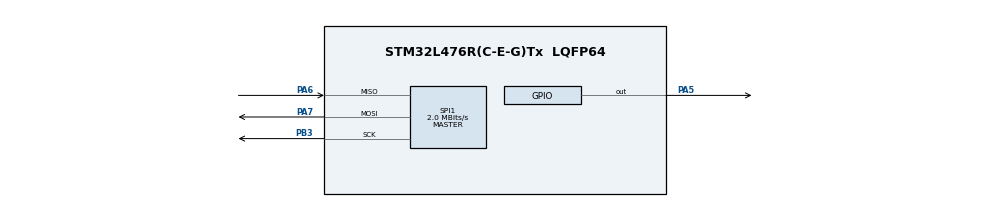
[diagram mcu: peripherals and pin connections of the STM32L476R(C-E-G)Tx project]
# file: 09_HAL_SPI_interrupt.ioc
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Mcu.Family=STM32L4
Mcu.Name=STM32L476R(C-E-G)Tx
Mcu.Package=LQFP64
NVIC.PriorityGroup=NVIC_PRIORITYGROUP_4
NVIC.SPI1_IRQn=true\:0\:0\:false\:true\:true\:1\:true\:true\:true
PA5.Signal=GPIO_Output
PA6.Mode=Full_Duplex_Master
PA6.Signal=SPI1_MISO
PA7.Mode=Full_Duplex_Master
PA7.Signal=SPI1_MOSI
PB3\ (JTDO-TRACESWO).Mode=Full_Duplex_Master
PB3\ (JTDO-TRACESWO).Signal=SPI1_SCK
ProjectManager.HeapSize=0x200
ProjectManager.StackSize=0x400
ProjectManager.TargetToolchain=STM32CubeIDE
RCC.HSE_VALUE=8000000
RCC.HSI_VALUE=16000000
RCC.LSE_VALUE=32768
RCC.MSI_VALUE=4000000
RCC.VCOOutputFreq_Value=32000000
SPI1.CalculateBaudRate=2.0 MBits/s
SPI1.DataSize=SPI_DATASIZE_8BIT
SPI1.Direction=SPI_DIRECTION_2LINES
SPI1.Mode=SPI_MODE_MASTER
SPI1.VirtualType=VM_MASTER
board=custom

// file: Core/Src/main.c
/* USER CODE BEGIN Header */
/**
  ******************************************************************************
  * @file           : main.c
  * @brief          : Main program body
  ******************************************************************************
  * @attention
  *
  * Copyright (c) 2026 STMicroelectronics.
  * All rights reserved.
  *
  * This software is licensed under terms that can be found in the LICENSE file
  * in the root directory of this software component.
  * If no LICENSE file comes with this software, it is provided AS-IS.
  *
  ******************************************************************************
  */
/* USER CODE END Header */
#include "main.h"

SPI_HandleTypeDef hspi1;

void SystemClock_Config(void);
static void MX_GPIO_Init(void);
static void MX_SPI1_Init(void);
static void MX_NVIC_Init(void);

/* USER CODE BEGIN 0 */
uint8_t txData[] = "HELLO";
/* USER CODE END 0 */

int main(void)
{

  /* MCU Configuration--------------------------------------------------------*/

  /* Reset of all peripherals, Initializes the Flash interface and the Systick. */
  HAL_Init();

  /* Configure the system clock */
  SystemClock_Config();

  /* Initialize all configured peripherals */
  MX_GPIO_Init();
  MX_SPI1_Init();

  /* Initialize interrupts */
  MX_NVIC_Init();

  /* Infinite loop */
  /* USER CODE BEGIN WHILE */
  while (1)
  {
	    while (1)
	    {
	        HAL_SPI_Transmit_IT(&hspi1, txData, sizeof(txData));

	        HAL_Delay(1000);
	    }

    /* USER CODE END WHILE */

  }
}

void SystemClock_Config(void)
{
  RCC_OscInitTypeDef RCC_OscInitStruct = {0};
  RCC_ClkInitTypeDef RCC_ClkInitStruct = {0};

  /** Configure the main internal regulator output voltage
  */
  if (HAL_PWREx_ControlVoltageScaling(PWR_REGULATOR_VOLTAGE_SCALE1) != HAL_OK)
  {
    Error_Handler();
  }

  /** Initializes the RCC Oscillators according to the specified parameters
  * in the RCC_OscInitTypeDef structure.
  */
  RCC_OscInitStruct.OscillatorType = RCC_OSCILLATORTYPE_MSI;
  RCC_OscInitStruct.MSIState = RCC_MSI_ON;
  RCC_OscInitStruct.MSICalibrationValue = 0;
  RCC_OscInitStruct.MSIClockRange = RCC_MSIRANGE_6;
  RCC_OscInitStruct.PLL.PLLState = RCC_PLL_NONE;
  if (HAL_RCC_OscConfig(&RCC_OscInitStruct) != HAL_OK)
  {
    Error_Handler();
  }

  /** Initializes the CPU, AHB and APB buses clocks
  */
  RCC_ClkInitStruct.ClockType = RCC_CLOCKTYPE_HCLK|RCC_CLOCKTYPE_SYSCLK
                              |RCC_CLOCKTYPE_PCLK1|RCC_CLOCKTYPE_PCLK2;
  RCC_ClkInitStruct.SYSCLKSource = RCC_SYSCLKSOURCE_MSI;
  RCC_ClkInitStruct.AHBCLKDivider = RCC_SYSCLK_DIV1;
  RCC_ClkInitStruct.APB1CLKDivider = RCC_HCLK_DIV1;
  RCC_ClkInitStruct.APB2CLKDivider = RCC_HCLK_DIV1;

  if (HAL_RCC_ClockConfig(&RCC_ClkInitStruct, FLASH_LATENCY_0) != HAL_OK)
  {
    Error_Handler();
  }
}

/**
  * @brief NVIC Configuration.
  * @retval None
  */
static void MX_NVIC_Init(void)
{
  /* SPI1_IRQn interrupt configuration */
  HAL_NVIC_SetPriority(SPI1_IRQn, 0, 0);
  HAL_NVIC_EnableIRQ(SPI1_IRQn);
}

static void MX_SPI1_Init(void)
{

  /* SPI1 parameter configuration*/
  hspi1.Instance = SPI1;
  hspi1.Init.Mode = SPI_MODE_MASTER;
  hspi1.Init.Direction = SPI_DIRECTION_2LINES;
  hspi1.Init.DataSize = SPI_DATASIZE_8BIT;
  hspi1.Init.CLKPolarity = SPI_POLARITY_LOW;
  hspi1.Init.CLKPhase = SPI_PHASE_1EDGE;
  hspi1.Init.NSS = SPI_NSS_SOFT;
  hspi1.Init.BaudRatePrescaler = SPI_BAUDRATEPRESCALER_2;
  hspi1.Init.FirstBit = SPI_FIRSTBIT_MSB;
  hspi1.Init.TIMode = SPI_TIMODE_DISABLE;
  hspi1.Init.CRCCalculation = SPI_CRCCALCULATION_DISABLE;
  hspi1.Init.CRCPolynomial = 7;
  hspi1.Init.CRCLength = SPI_CRC_LENGTH_DATASIZE;
  hspi1.Init.NSSPMode = SPI_NSS_PULSE_ENABLE;
  if (HAL_SPI_Init(&hspi1) != HAL_OK)
  {
    Error_Handler();
  }

}

static void MX_GPIO_Init(void)
{
  GPIO_InitTypeDef GPIO_InitStruct = {0};

  /* GPIO Ports Clock Enable */
  __HAL_RCC_GPIOA_CLK_ENABLE();
  __HAL_RCC_GPIOB_CLK_ENABLE();

  /*Configure GPIO pin Output Level */
  HAL_GPIO_WritePin(GPIOA, GPIO_PIN_5, GPIO_PIN_RESET);

  /*Configure GPIO pin : PA5 */
  GPIO_InitStruct.Pin = GPIO_PIN_5;
  GPIO_InitStruct.Mode = GPIO_MODE_OUTPUT_PP;
  GPIO_InitStruct.Pull = GPIO_NOPULL;
  GPIO_InitStruct.Speed = GPIO_SPEED_FREQ_LOW;
  HAL_GPIO_Init(GPIOA, &GPIO_InitStruct);

}

/* USER CODE BEGIN 4 */
void HAL_SPI_TxCpltCallback(SPI_HandleTypeDef *hspi)
{
    if(hspi->Instance == SPI1)
    {
        HAL_GPIO_TogglePin(GPIOA, GPIO_PIN_5);

        /* Put breakpoint here */
    }
}
/* USER CODE END 4 */

void Error_Handler(void)
{
  __disable_irq();
  while (1)
  {
  }
}
